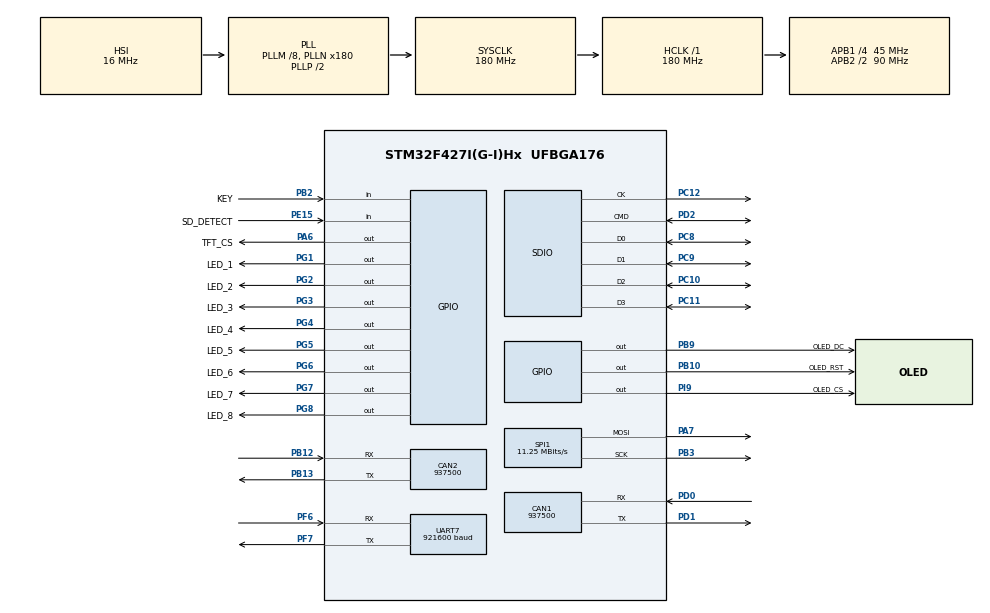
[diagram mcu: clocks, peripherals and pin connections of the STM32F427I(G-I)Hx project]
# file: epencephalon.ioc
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CAN1.CalculateBaudRate=937500
CAN1.CalculateTimeBit=1066
CAN1.CalculateTimeQuantum=355.55555555555554
CAN2.CalculateBaudRate=937500
CAN2.CalculateTimeBit=1066
CAN2.CalculateTimeQuantum=355.55555555555554
Dma.Request0=SPI1_TX
Dma.Request1=SDIO_TX
Dma.Request2=SDIO_RX
Dma.Request3=UART7_TX
Dma.SDIO_RX.2.Direction=DMA_PERIPH_TO_MEMORY
Dma.SDIO_RX.2.FIFOMode=DMA_FIFOMODE_ENABLE
Dma.SDIO_RX.2.FIFOThreshold=DMA_FIFO_THRESHOLD_FULL
Dma.SDIO_RX.2.Instance=DMA2_Stream3
Dma.SDIO_RX.2.MemBurst=DMA_MBURST_INC4
Dma.SDIO_RX.2.MemDataAlignment=DMA_MDATAALIGN_WORD
Dma.SDIO_RX.2.MemInc=DMA_MINC_ENABLE
Dma.SDIO_RX.2.Mode=DMA_PFCTRL
Dma.SDIO_RX.2.PeriphBurst=DMA_PBURST_INC4
Dma.SDIO_RX.2.PeriphDataAlignment=DMA_PDATAALIGN_WORD
Dma.SDIO_RX.2.PeriphInc=DMA_PINC_DISABLE
Dma.SDIO_RX.2.Priority=DMA_PRIORITY_LOW
Dma.SDIO_TX.1.Direction=DMA_MEMORY_TO_PERIPH
Dma.SDIO_TX.1.FIFOMode=DMA_FIFOMODE_ENABLE
Dma.SDIO_TX.1.FIFOThreshold=DMA_FIFO_THRESHOLD_FULL
Dma.SDIO_TX.1.Instance=DMA2_Stream6
Dma.SDIO_TX.1.MemBurst=DMA_MBURST_INC4
Dma.SDIO_TX.1.MemDataAlignment=DMA_MDATAALIGN_WORD
Dma.SDIO_TX.1.MemInc=DMA_MINC_ENABLE
Dma.SDIO_TX.1.Mode=DMA_PFCTRL
Dma.SDIO_TX.1.PeriphBurst=DMA_PBURST_INC4
Dma.SDIO_TX.1.PeriphDataAlignment=DMA_PDATAALIGN_WORD
Dma.SDIO_TX.1.PeriphInc=DMA_PINC_DISABLE
Dma.SDIO_TX.1.Priority=DMA_PRIORITY_LOW
Dma.SPI1_TX.0.Direction=DMA_MEMORY_TO_PERIPH
Dma.SPI1_TX.0.FIFOMode=DMA_FIFOMODE_DISABLE
Dma.SPI1_TX.0.Instance=DMA2_Stream5
Dma.SPI1_TX.0.MemDataAlignment=DMA_MDATAALIGN_BYTE
Dma.SPI1_TX.0.MemInc=DMA_MINC_ENABLE
Dma.SPI1_TX.0.Mode=DMA_NORMAL
Dma.SPI1_TX.0.PeriphDataAlignment=DMA_PDATAALIGN_BYTE
Dma.SPI1_TX.0.PeriphInc=DMA_PINC_DISABLE
Dma.SPI1_TX.0.Priority=DMA_PRIORITY_LOW
Dma.UART7_TX.3.Direction=DMA_MEMORY_TO_PERIPH
Dma.UART7_TX.3.FIFOMode=DMA_FIFOMODE_DISABLE
Dma.UART7_TX.3.Instance=DMA1_Stream1
Dma.UART7_TX.3.MemDataAlignment=DMA_MDATAALIGN_BYTE
Dma.UART7_TX.3.MemInc=DMA_MINC_ENABLE
Dma.UART7_TX.3.Mode=DMA_NORMAL
Dma.UART7_TX.3.PeriphDataAlignment=DMA_PDATAALIGN_BYTE
Dma.UART7_TX.3.PeriphInc=DMA_PINC_DISABLE
Dma.UART7_TX.3.Priority=DMA_PRIORITY_LOW
FATFS.BSP.number=1
FATFS0.BSP.STBoard=false
FATFS0.BSP.api=Unknown
FATFS0.BSP.instance=PE15
FATFS0.BSP.ip=GPIO
FATFS0.BSP.mode=Input
FATFS0.BSP.name=Detect_SDIO
FATFS0.BSP.solution=PE15
FREERTOS.Tasks01=defaultTask,24,128,StartDefaultTask,Default,NULL,Dynamic,NULL,NULL;myTask02,8,128,StartTask02,Default,NULL,Dynamic,NULL,NULL;myTask03,8,128,StartTask03,Default,NULL,Dynamic,NULL,NULL
FREERTOS.configCHECK_FOR_STACK_OVERFLOW=2
FREERTOS.configUSE_MALLOC_FAILED_HOOK=1
Mcu.Family=STM32F4
Mcu.Name=STM32F427I(G-I)Hx
Mcu.Package=UFBGA176
NVIC.CAN1_RX0_IRQn=true\:5\:0\:false\:false\:true\:true\:true\:true\:true
NVIC.CAN1_RX1_IRQn=true\:5\:0\:false\:false\:true\:true\:true\:true\:true
NVIC.CAN1_SCE_IRQn=true\:5\:0\:false\:false\:true\:true\:true\:true\:true
NVIC.CAN1_TX_IRQn=true\:5\:0\:false\:false\:true\:true\:true\:true\:true
NVIC.CAN2_RX0_IRQn=true\:5\:0\:false\:false\:true\:true\:true\:true\:true
NVIC.CAN2_RX1_IRQn=true\:5\:0\:false\:false\:true\:true\:true\:true\:true
NVIC.CAN2_SCE_IRQn=true\:5\:0\:false\:false\:true\:true\:true\:true\:true
NVIC.CAN2_TX_IRQn=true\:5\:0\:false\:false\:true\:true\:true\:true\:true
NVIC.DMA1_Stream1_IRQn=true\:5\:0\:false\:false\:true\:true\:false\:true\:true
NVIC.DMA2_Stream3_IRQn=true\:5\:0\:false\:false\:true\:true\:false\:true\:true
NVIC.DMA2_Stream5_IRQn=true\:5\:0\:false\:false\:true\:false\:false\:true\:true
NVIC.DMA2_Stream6_IRQn=true\:5\:0\:false\:false\:true\:true\:false\:true\:true
NVIC.PriorityGroup=NVIC_PRIORITYGROUP_4
NVIC.SDIO_IRQn=true\:5\:0\:false\:false\:true\:true\:true\:true\:true
NVIC.TIM2_IRQn=true\:15\:0\:false\:false\:true\:false\:false\:true\:true
NVIC.TimeBase=TIM2_IRQn
NVIC.TimeBaseIP=TIM2
NVIC.UART7_IRQn=true\:5\:0\:false\:false\:true\:true\:true\:true\:true
PA13.Mode=Serial_Wire
PA13.Signal=SYS_JTMS-SWDIO
PA14.Mode=Serial_Wire
PA14.Signal=SYS_JTCK-SWCLK
PA6.GPIO_Label=TFT_CS
PA6.GPIO_Speed=GPIO_SPEED_FREQ_HIGH
PA6.PinState=GPIO_PIN_SET
PA6.Signal=GPIO_Output
PA7.Mode=TX_Only_Simplex_Unidirect_Master
PA7.Signal=SPI1_MOSI
PB10.GPIO_Label=OLED_RST
PB10.Signal=GPIO_Output
PB12.Mode=CAN_Activate
PB12.Signal=CAN2_RX
PB13.Mode=CAN_Activate
PB13.Signal=CAN2_TX
PB2/BOOT1.GPIO_Label=KEY
PB2/BOOT1.GPIO_PuPd=GPIO_PULLUP
PB2/BOOT1.Signal=GPIO_Input
PB3.Mode=TX_Only_Simplex_Unidirect_Master
PB3.Signal=SPI1_SCK
PB9.GPIO_Label=OLED_DC
PB9.Signal=GPIO_Output
PC10.Mode=SD_4_bits_Wide_bus
PC10.Signal=SDIO_D2
PC11.Mode=SD_4_bits_Wide_bus
PC11.Signal=SDIO_D3
PC12.Mode=SD_4_bits_Wide_bus
PC12.Signal=SDIO_CK
PC14/OSC32_IN.Mode=LSE-External-Oscillator
PC14/OSC32_IN.Signal=RCC_OSC32_IN
PC15/OSC32_OUT.Mode=LSE-External-Oscillator
PC15/OSC32_OUT.Signal=RCC_OSC32_OUT
PC8.Mode=SD_4_bits_Wide_bus
PC8.Signal=SDIO_D0
PC9.Mode=SD_4_bits_Wide_bus
PC9.Signal=SDIO_D1
PD0.Mode=CAN_Activate
PD0.Signal=CAN1_RX
PD1.Mode=CAN_Activate
PD1.Signal=CAN1_TX
PD2.Mode=SD_4_bits_Wide_bus
PD2.Signal=SDIO_CMD
PE15.GPIO_Label=SD_DETECT
PE15.Signal=GPIO_Input
PF6.Mode=Asynchronous
PF6.Signal=UART7_RX
PF7.Mode=Asynchronous
PF7.Signal=UART7_TX
PG1.GPIO_Label=LED_1
PG1.Signal=GPIO_Output
PG2.GPIO_Label=LED_2
PG2.Signal=GPIO_Output
PG3.GPIO_Label=LED_3
PG3.Signal=GPIO_Output
PG4.GPIO_Label=LED_4
PG4.Signal=GPIO_Output
PG5.GPIO_Label=LED_5
PG5.Signal=GPIO_Output
PG6.GPIO_Label=LED_6
PG6.Signal=GPIO_Output
PG7.GPIO_Label=LED_7
PG7.Signal=GPIO_Output
PG8.GPIO_Label=LED_8
PG8.Signal=GPIO_Output
PH0/OSC_IN.Mode=HSE-External-Oscillator
PH0/OSC_IN.Signal=RCC_OSC_IN
PH1/OSC_OUT.Mode=HSE-External-Oscillator
PH1/OSC_OUT.Signal=RCC_OSC_OUT
PI9.GPIO_Label=OLED_CS
PI9.GPIO_Speed=GPIO_SPEED_FREQ_HIGH
PI9.PinState=GPIO_PIN_SET
PI9.Signal=GPIO_Output
ProjectManager.HeapSize=0x200
ProjectManager.StackSize=0x400
ProjectManager.TargetToolchain=CMake
RCC.48MHZClocksFreq_Value=45000000
RCC.AHBFreq_Value=180000000
RCC.APB1CLKDivider=RCC_HCLK_DIV4
RCC.APB1Freq_Value=45000000
RCC.APB1TimFreq_Value=90000000
RCC.APB2CLKDivider=RCC_HCLK_DIV2
RCC.APB2Freq_Value=90000000
RCC.APB2TimFreq_Value=180000000
RCC.CortexFreq_Value=180000000
RCC.HCLKFreq_Value=180000000
RCC.HSE_VALUE=25000000
RCC.HSI_VALUE=16000000
RCC.PLLM=8
RCC.PLLN=180
RCC.PLLQ=8
RCC.SYSCLKFreq_VALUE=180000000
RCC.SYSCLKSource=RCC_SYSCLKSOURCE_PLLCLK
RCC.VCOOutputFreq_Value=360000000
SPI1.BaudRatePrescaler=SPI_BAUDRATEPRESCALER_8
SPI1.CalculateBaudRate=11.25 MBits/s
SPI1.Direction=SPI_DIRECTION_2LINES
SPI1.Mode=SPI_MODE_MASTER
SPI1.VirtualType=VM_MASTER
UART7.BaudRate=921600
UART7.VirtualMode=Asynchronous
VP_FATFS_VS_SDIO.Mode=SDIO
VP_FREERTOS_VS_CMSIS_V2.Mode=CMSIS_V2
VP_SYS_VS_tim2.Mode=TIM2
VP_TIM3_VS_ClockSourceINT.Mode=Internal
VP_TIM4_VS_ClockSourceINT.Mode=Internal
VP_TIM5_VS_ClockSourceINT.Mode=Internal
VP_TIM6_VS_ClockSourceINT.Mode=Enable_Timer
VP_TIM7_VS_ClockSourceINT.Mode=Enable_Timer
board=custom

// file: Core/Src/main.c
/* USER CODE BEGIN Header */
/**
  ******************************************************************************
  * @file           : main.c
  * @brief          : Main program body
  ******************************************************************************
  * @attention
  *
  * Copyright (c) 2026 STMicroelectronics.
  * All rights reserved.
  *
  * This software is licensed under terms that can be found in the LICENSE file
  * in the root directory of this software component.
  * If no LICENSE file comes with this software, it is provided AS-IS.
  *
  ******************************************************************************
  */
/* USER CODE END Header */
#include "main.h"
#include "cmsis_os.h"
#include "can.h"
#include "dma.h"
#include "fatfs.h"
#include "sdio.h"
#include "spi.h"
#include "tim.h"
#include "usart.h"
#include "gpio.h"

void SystemClock_Config(void);
void MX_FREERTOS_Init(void);

int main(void)
{

  /* MCU Configuration--------------------------------------------------------*/

  /* Reset of all peripherals, Initializes the Flash interface and the Systick. */
  HAL_Init();

  /* Configure the system clock */
  SystemClock_Config();

  /* Initialize all configured peripherals */
  MX_GPIO_Init();
  MX_DMA_Init();
  MX_SDIO_SD_Init();
  MX_FATFS_Init();
  MX_SPI1_Init();
  MX_TIM3_Init();
  MX_TIM4_Init();
  MX_TIM5_Init();
  MX_TIM6_Init();
  MX_TIM7_Init();
  MX_UART7_Init();
  MX_CAN1_Init();
  MX_CAN2_Init();

  /* Init scheduler */
  osKernelInitialize();  /* Call init function for freertos objects (in cmsis_os2.c) */
  MX_FREERTOS_Init();

  /* Start scheduler */
  osKernelStart();

  /* We should never get here as control is now taken by the scheduler */

  /* Infinite loop */
  while (1)
  {

  }
}

void SystemClock_Config(void)
{
  RCC_OscInitTypeDef RCC_OscInitStruct = {0};
  RCC_ClkInitTypeDef RCC_ClkInitStruct = {0};

  /** Configure the main internal regulator output voltage
  */
  __HAL_RCC_PWR_CLK_ENABLE();
  __HAL_PWR_VOLTAGESCALING_CONFIG(PWR_REGULATOR_VOLTAGE_SCALE1);

  /** Initializes the RCC Oscillators according to the specified parameters
  * in the RCC_OscInitTypeDef structure.
  */
  RCC_OscInitStruct.OscillatorType = RCC_OSCILLATORTYPE_HSI;
  RCC_OscInitStruct.HSIState = RCC_HSI_ON;
  RCC_OscInitStruct.HSICalibrationValue = RCC_HSICALIBRATION_DEFAULT;
  RCC_OscInitStruct.PLL.PLLState = RCC_PLL_ON;
  RCC_OscInitStruct.PLL.PLLSource = RCC_PLLSOURCE_HSI;
  RCC_OscInitStruct.PLL.PLLM = 8;
  RCC_OscInitStruct.PLL.PLLN = 180;
  RCC_OscInitStruct.PLL.PLLP = RCC_PLLP_DIV2;
  RCC_OscInitStruct.PLL.PLLQ = 8;
  if (HAL_RCC_OscConfig(&RCC_OscInitStruct) != HAL_OK)
  {
    Error_Handler();
  }

  /** Activate the Over-Drive mode
  */
  if (HAL_PWREx_EnableOverDrive() != HAL_OK)
  {
    Error_Handler();
  }

  /** Initializes the CPU, AHB and APB buses clocks
  */
  RCC_ClkInitStruct.ClockType = RCC_CLOCKTYPE_HCLK|RCC_CLOCKTYPE_SYSCLK
                              |RCC_CLOCKTYPE_PCLK1|RCC_CLOCKTYPE_PCLK2;
  RCC_ClkInitStruct.SYSCLKSource = RCC_SYSCLKSOURCE_PLLCLK;
  RCC_ClkInitStruct.AHBCLKDivider = RCC_SYSCLK_DIV1;
  RCC_ClkInitStruct.APB1CLKDivider = RCC_HCLK_DIV4;
  RCC_ClkInitStruct.APB2CLKDivider = RCC_HCLK_DIV2;

  if (HAL_RCC_ClockConfig(&RCC_ClkInitStruct, FLASH_LATENCY_5) != HAL_OK)
  {
    Error_Handler();
  }
}

void HAL_TIM_PeriodElapsedCallback(TIM_HandleTypeDef *htim)
{
  if (htim->Instance == TIM2)
  {
    HAL_IncTick();
  }
}

void Error_Handler(void)
{
  __disable_irq();
  while (1)
  {
  }
}

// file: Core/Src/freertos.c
/* USER CODE BEGIN Header */
/**
  ******************************************************************************
  * File Name          : freertos.c
  * Description        : Code for freertos applications
  ******************************************************************************
  * @attention
  *
  * Copyright (c) 2026 STMicroelectronics.
  * All rights reserved.
  *
  * This software is licensed under terms that can be found in the LICENSE file
  * in the root directory of this software component.
  * If no LICENSE file comes with this software, it is provided AS-IS.
  *
  ******************************************************************************
  */
/* USER CODE END Header */

#include "FreeRTOS.h"
#include "task.h"
#include "main.h"
#include "cmsis_os.h"

/* USER CODE BEGIN Includes */
#include "app_main.h"
/* USER CODE END Includes */

/* USER CODE BEGIN Variables */
/* Recorded by the two hooks below and read with the debugger. Plain .bss:
 * a stack overflow hook runs on a stack that is by definition already
 * damaged, so nothing here may call printf, allocate, or take a lock. */
volatile uint32_t g_rtosFaultKind = 0;   /* 1 = stack overflow, 2 = malloc failed */
volatile uint32_t g_rtosFaultCount = 0;
volatile char     g_rtosFaultTask[configMAX_TASK_NAME_LEN] = {0};
volatile uint32_t g_rtosHeapFreeAtFault = 0;

/* USER CODE END Variables */
/* Definitions for defaultTask */
osThreadId_t defaultTaskHandle;
const osThreadAttr_t defaultTask_attributes = {
  .name = "defaultTask",
  .stack_size = 128 * 4,
  .priority = (osPriority_t) osPriorityNormal,
};
/* Definitions for myTask02 */
osThreadId_t myTask02Handle;
const osThreadAttr_t myTask02_attributes = {
  .name = "myTask02",
  .stack_size = 128 * 4,
  .priority = (osPriority_t) osPriorityLow,
};
/* Definitions for myTask03 */
osThreadId_t myTask03Handle;
const osThreadAttr_t myTask03_attributes = {
  .name = "myTask03",
  .stack_size = 128 * 4,
  .priority = (osPriority_t) osPriorityLow,
};

void StartDefaultTask(void *argument);
void StartTask02(void *argument);
void StartTask03(void *argument);

void MX_FREERTOS_Init(void); /* (MISRA C 2004 rule 8.1) */

/* Hook prototypes */
void vApplicationStackOverflowHook(xTaskHandle xTask, signed char *pcTaskName);
void vApplicationMallocFailedHook(void)
{
  /* pvPortMalloc() returned NULL: a task, queue, timer or semaphore could not
   * be created. configTOTAL_HEAP_SIZE is 15360 B and osThreadNew draws from
   * it, so this is the counter that catches a stack size raised past what the
   * heap can serve. Same constraints as above -- record only. */
  g_rtosFaultKind = 2u;
  ++g_rtosFaultCount;
  g_rtosHeapFreeAtFault = (uint32_t)xPortGetFreeHeapSize();

  __disable_irq();
  for (;;)
  {
    GPIOG->ODR = (GPIOG->ODR & ~(0xFFu << 1)) | ((uint32_t)(uint8_t)~0x0Fu << 1);
    for (volatile uint32_t d = 0; d < 900000u; ++d) { }
    GPIOG->ODR = (GPIOG->ODR & ~(0xFFu << 1)) | ((uint32_t)(uint8_t)~0xF0u << 1);
    for (volatile uint32_t d = 0; d < 900000u; ++d) { }
  }
}
/* USER CODE END 5 */

void MX_FREERTOS_Init(void) {

  /* Create the thread(s) */
  /* creation of defaultTask */
  defaultTaskHandle = osThreadNew(StartDefaultTask, NULL, &defaultTask_attributes);

  /* creation of myTask02 */
  myTask02Handle = osThreadNew(StartTask02, NULL, &myTask02_attributes);

  /* creation of myTask03 */
  myTask03Handle = osThreadNew(StartTask03, NULL, &myTask03_attributes);

}

void StartDefaultTask(void *argument)
{
  /* USER CODE BEGIN StartDefaultTask */
  /* 交给 C++ 应用层，不返回 */
  app_main();
  /* USER CODE END StartDefaultTask */
}

void StartTask02(void *argument)
{
  for(;;)
  {
    osDelay(1);
  }
}

void StartTask03(void *argument)
{
  for(;;)
  {
    osDelay(1);
  }
}
